# PY32F032xx register map
Vendor: Puya; Series: PY32F0; File version: 1.0.0
CPU: CM0+ r0p1, little endian, no MPU, no FPU, 4 interrupt priority bits
Registers are 32-bit, read-write, reset 0x0 unless marked. A register's access mark holds for its fields unless they carry their own. Offsets are from the block's base; [hi:lo] are bit positions; {n}, {i} and the like mark numbered series.

## TIM3
Base 0x40000400
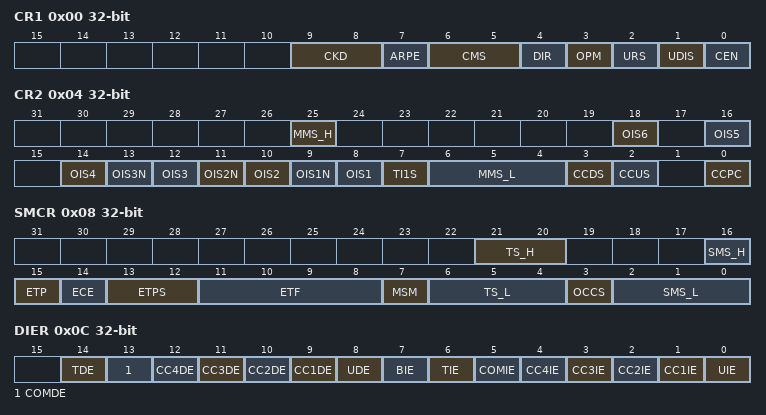
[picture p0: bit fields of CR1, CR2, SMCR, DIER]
0x00 CR1
  [9:8] CKD
    1=0; 2=1
  [7] ARPE
  [6:5] CMS
    1=0; 2=1
  [4] DIR
  [3] OPM
  [2] URS
  [1] UDIS
  [0] CEN
0x04 CR2
  [25] MMS_H, [2n+6] OIS{n} (n=1..6), [13] OIS3N, [11] OIS2N, [9] OIS1N, [7] TI1S, [6:4] MMS_L, [3] CCDS, [2] CCUS, [0] CCPC
0x08 SMCR
  [21:20] TS_H
  [16] SMS_H
  [15] ETP
  [14] ECE
  [13:12] ETPS
    1=0; 2=1
  [11:8] ETF
    1=0; 2=1; 4=2; 8=3
  [7] MSM
  [6:4] TS_L
  [3] OCCS
  [2:0] SMS_L
0x0C DIER
  [14] TDE, [13] COMDE, [n+8] CC{n}DE (n=1..4), [8] UDE, [7] BIE, [6] TIE, [5] COMIE, [n] CC{n}IE (n=1..4), [0] UIE
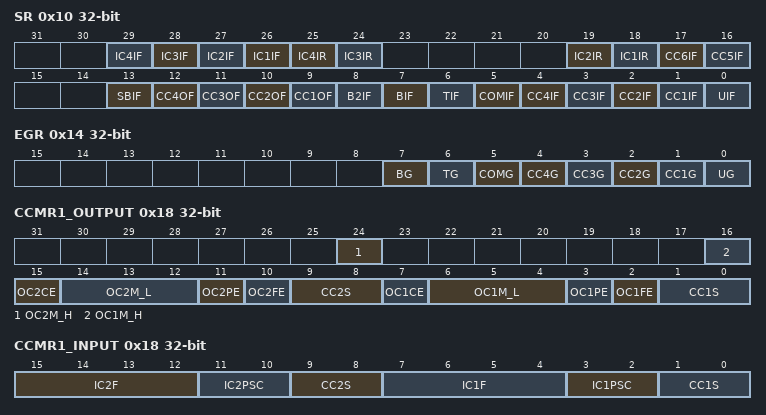
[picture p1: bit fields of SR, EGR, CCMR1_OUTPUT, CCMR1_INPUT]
0x10 SR
  [n+25] IC{n}IF (n=1..4), [25] IC4IR, [24] IC3IR, [19] IC2IR, [18] IC1IR, [17] CC6IF, [16] CC5IF, [13] SBIF, [n+8] CC{n}OF (n=1..4), [8] B2IF, [7] BIF, [6] TIF, [5] COMIF, [n] CC{n}IF (n=1..4), [0] UIF
0x14 EGR
  [7] BG, [6] TG, [5] COMG, [n] CC{n}G (n=1..4), [0] UG
0x18 CCMR1_OUTPUT
  [24] OC2M_H, [16] OC1M_H, [15] OC2CE, [14:12] OC2M_L, [11] OC2PE, [10] OC2FE, [9:8] CC2S, [7] OC1CE, [6:4] OC1M_L, [3] OC1PE, [2] OC1FE, [1:0] CC1S
0x18 CCMR1_INPUT (alternate view of CCMR1_OUTPUT)
  [15:12] IC2F, [11:10] IC2PSC, [9:8] CC2S, [7:4] IC1F, [3:2] IC1PSC, [1:0] CC1S
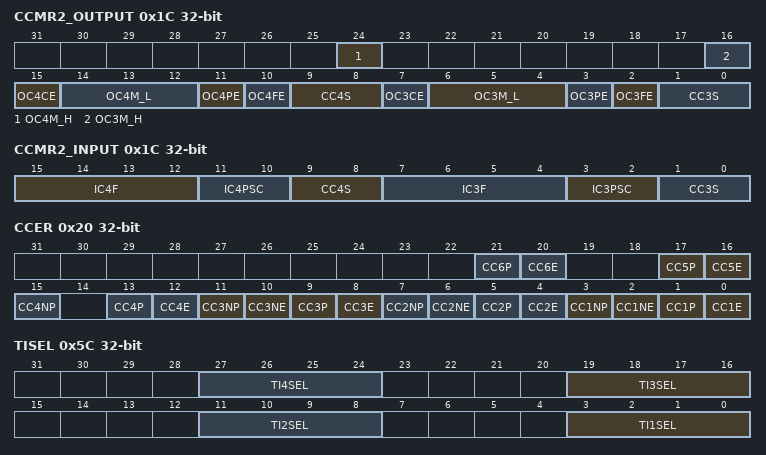
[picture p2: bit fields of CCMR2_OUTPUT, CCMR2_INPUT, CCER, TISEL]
0x1C CCMR2_OUTPUT
  [24] OC4M_H, [16] OC3M_H, [15] OC4CE, [14:12] OC4M_L, [11] OC4PE, [10] OC4FE, [9:8] CC4S, [7] OC3CE, [6:4] OC3M_L, [3] OC3PE, [2] OC3FE, [1:0] CC3S
0x1C CCMR2_INPUT (alternate view of CCMR2_OUTPUT)
  [15:12] IC4F, [11:10] IC4PSC, [9:8] CC4S, [7:4] IC3F, [3:2] IC3PSC, [1:0] CC3S
0x20 CCER
  [4n-3] CC{n}P (n=1..6), [4n-4] CC{n}E (n=1..6), [4n-1] CC{n}NP (n=1..4), [10] CC3NE, [6] CC2NE, [2] CC1NE
0x24 CNT
  [15:0] CNT
0x28 PSC
  [15:0] PSC
0x2C ARR
  [15:0] ARR
{0x30+4i} CCR{i} (i=1..4)
  [15:0] CCR{i}
0x5C TISEL
  [all] fields
    1=0; 2=1; 4=2; 8=3
  [8n-5:8n-8] TI{n}SEL (n=1..4)
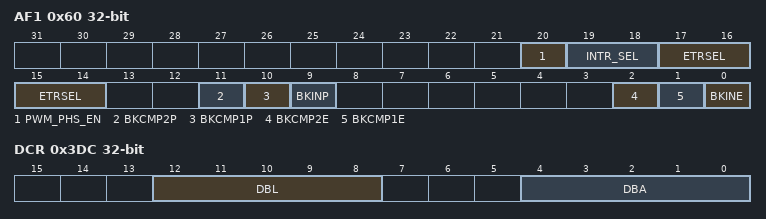
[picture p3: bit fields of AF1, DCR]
0x60 AF1
  [20] PWM_PHS_EN
  [19:18] INTR_SEL
    1=0; 2=1
  [17:14] ETRSEL
    1=0; 2=1; 4=2; 8=3
  [11] BKCMP2P
  [10] BKCMP1P
  [9] BKINP
  [2] BKCMP2E
  [1] BKCMP1E
  [0] BKINE
0x64 AF2
  [18:16] OCRSEL
    1=0; 2=1; 4=2
0x3DC DCR
  [12:8] DBL
    1=0; 2=1; 4=2; 8=3; 16=4
  [4:0] DBA
    1=0; 2=1; 4=2; 8=3; 16=4
0x3E0 DMAR
  [31:0] DMAB

## UART1
Base 0x40004800
Same registers: UART2 0x40004C00
0x00 DR
  [8:0] DR — Receive/send data register
0x04 BRR
  [15:0] BRR — Baud rate register
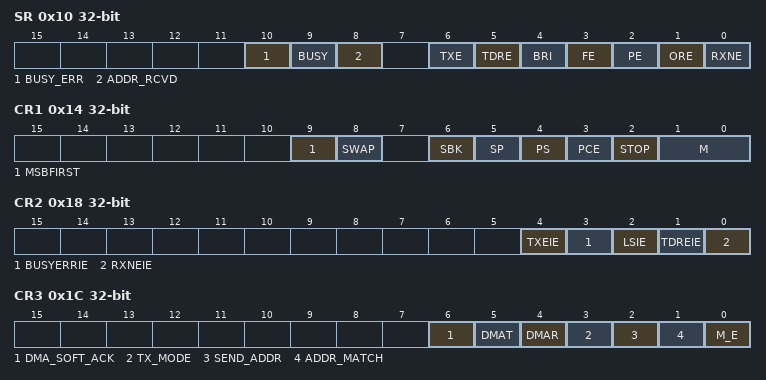
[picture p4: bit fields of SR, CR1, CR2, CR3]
0x10 SR
  [10] BUSY_ERR — Busy Detect Error
  [9] BUSY ro — UART Busy
  [8] ADDR_RCVD — Address Received Bit
  [6] TXE ro — Transmitter Empty bit
  [5] TDRE ro — Transmit Holding Register Empty bit
  [4] BRI — Break Interrupt bit
  [3] FE — Framing Error bit
  [2] PE — Parity Error bit
  [1] ORE — Overrun error bit
  [0] RXNE ro — Receive register not empty
0x14 CR1
  [9] MSBFIRST — MSB first mode
  [8] SWAP — TX/RX pin swap
  [6] SBK — Send Break
  [5] SP — Stick Parity
  [4] PS — Even Parity Select
  [3] PCE — Parity Enable
  [2] STOP — Number of stop bits
  [1:0] M — Data Length Select
    1=0; 2=1
0x18 CR2
  [4] TXEIE — Enable tx empty interruption
  [3] BUSYERRIE — Enable Busyerr state interruption
  [2] LSIE — Enable Receiver Line Status Interrupt
  [1] TDREIE — Enable Transmit Holding Register Empty Interrupt
  [0] RXNEIE — Enable Received Data Available Interrupt
0x1C CR3
  [6] DMA_SOFT_ACK — DMA software ack
  [5] DMAT — DMA transmit enable
  [4] DMAR — DMA receive enable
  [3] TX_MODE — Transmit mode control bit
  [2] SEND_ADDR — Send address control bit
  [1] ADDR_MATCH — Address Match Mode
  [0] M_E — Extension for DLS
0x20 RAR
  [7:0] RAR — Receive address matching register
0x24 TAR
  [7:0] TAR — Transmit address matching register
0x28 BRRF
  [3:0] BRRF — Baud rate fractional register
    1=0; 2=1; 4=2; 8=3

## USART1 — Universal synchronous asynchronous receivertransmitter
Base 0x40013800
Same registers: USART2 0x40004400
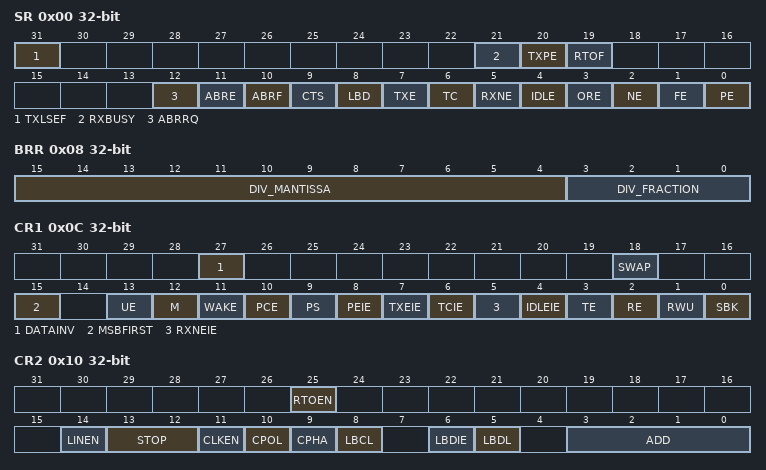
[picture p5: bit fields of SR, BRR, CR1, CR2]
0x00 SR — Status register
  [31] TXLSEF ro
  [21] RXBUSY ro
  [20] TXPE
  [19] RTOF — rto flag
  [12] ABRRQ ro — auto baud rate req
  [11] ABRE ro — auto baud rateerror
  [10] ABRF ro — auto baud rate flag
  [9] CTS — cts flag
  [8] LBD — LIN break detection flag
  [7] TXE ro — Transmit data register empty
  [6] TC — Transmission complete
  [5] RXNE — Read data register not empty
  [4] IDLE ro
  [3] ORE ro — overrun error
  [2] NE ro — Noise error flag
  [1] FE ro — Framing error
  [0] PE ro — Parity error
0x04 DR — Data register
  [8:0] DR
0x08 BRR — Baud rate register
  [15:4] DIV_MANTISSA
  [3:0] DIV_FRACTION
    1=0; 2=1; 4=2; 8=3
0x0C CR1 — Control register 1
  [27] DATAINV — data inverse
  [18] SWAP
  [15] MSBFIRST
  [13] UE — uesart enable
  [12] M — word length
  [11] WAKE — Wakeup method
  [10] PCE — Parity control enable
  [9] PS — Parity selection
  [8] PEIE — PE interrupt enable
  [7] TXEIE — txe
  [6] TCIE — send complete int enable
  [5] RXNEIE — RXNE interrupt enable
  [4] IDLEIE — IDLE interrupt enable
  [3] TE — Transmitter enable
  [2] RE — Receiver enable
  [1] RWU — Receiver wakeup
  [0] SBK — Send break
0x10 CR2 — Control register 2
  [25] RTOEN — Receiver timeout enable
  [14] LINEN — lin enable
  [13:12] STOP — stop bit
    1=0; 2=1
  [11] CLKEN
  [10] CPOL
  [9] CPHA
  [8] LBCL
  [6] LBDIE — lin break enable
  [5] LBDL — LIN break detection length
  [3:0] ADD — mute addr
    1=0; 2=1; 4=2; 8=3
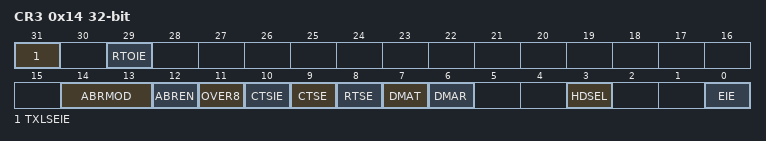
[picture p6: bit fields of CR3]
0x14 CR3 — Control register 3
  [31] TXLSEIE — tx register empty int enable
  [29] RTOIE — rto int enable
  [14:13] ABRMOD — auto baud mod
    1=0; 2=1
  [12] ABREN — autobaud enable
  [11] OVER8 — oversampling
  [10] CTSIE — cts int enable
  [9] CTSE — cts enable
  [8] RTSE — rts enable
  [7] DMAT — dma tx enable
  [6] DMAR — dma rx enable
  [3] HDSEL
  [0] EIE — error int enable
0x1C RTOR
  [23:0] RTO — receive timeout

## WWDG — Window watchdog
Base 0x40002C00
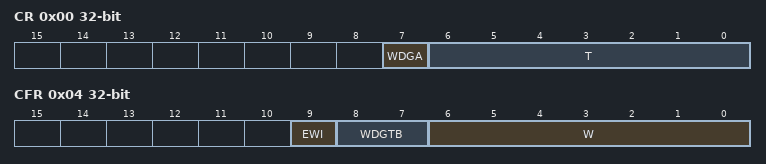
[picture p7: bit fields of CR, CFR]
0x00 CR — Control register (WWDG_CR)
  [7] WDGA — WWDG Activation
  [6:0] T — wwdg counter bit
    1=0; 2=1; 4=2; 8=3; 16=4; 32=5; 64=6
0x04 CFR — Configuration register(WWDG_CFR)
  [9] EWI — Early wakeup interrupt
  [8:7] WDGTB — time base bit
    1=0; 2=1
  [6:0] W — window value bit
    1=0; 2=1; 4=2; 8=3; 16=4; 32=5; 64=6
0x08 SR 16-bit — Status register (WWDG_SR)
  [0] EWIF — Early wakeup interrupt flag
